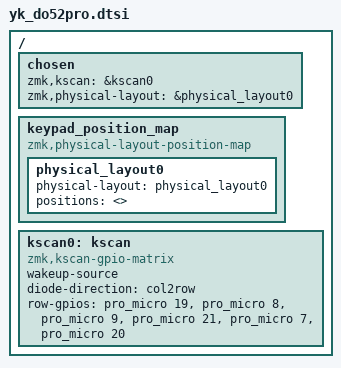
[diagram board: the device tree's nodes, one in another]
/*
 * Copyright (c) 2020 Pete Johanson
 *
 * SPDX-License-Identifier: MIT
 */

#include <dt-bindings/zmk/matrix_transform.h>

#include <physical_layouts.dtsi>
#include "yk_do52pro-layouts.dtsi"
/ {
    chosen {
       
        zmk,kscan = &kscan0;
        //zmk,matrix-transform = &default_transform;
        zmk,physical-layout = &physical_layout0;
        
    };

    keypad_position_map {
        compatible = "zmk,physical-layout-position-map";

        physical_layout0 {
            physical-layout = <&physical_layout0>;
            positions = <>;
        };
    };

    kscan0: kscan {
        compatible = "zmk,kscan-gpio-matrix";
        wakeup-source;

        diode-direction = "col2row";
        row-gpios
            = <&pro_micro 19 (GPIO_ACTIVE_HIGH | GPIO_PULL_DOWN)>
            , <&pro_micro 8 (GPIO_ACTIVE_HIGH | GPIO_PULL_DOWN)>
            , <&pro_micro 9 (GPIO_ACTIVE_HIGH | GPIO_PULL_DOWN)>
            , <&pro_micro 21 (GPIO_ACTIVE_HIGH | GPIO_PULL_DOWN)>
            , <&pro_micro 7 (GPIO_ACTIVE_HIGH | GPIO_PULL_DOWN)>
            , <&pro_micro 20 (GPIO_ACTIVE_HIGH | GPIO_PULL_DOWN)>
            ;

    };

    // TODO: per-key RGB node(s)?
};


